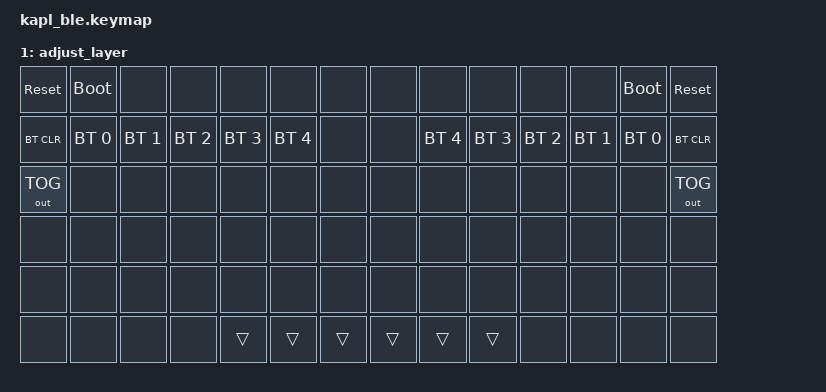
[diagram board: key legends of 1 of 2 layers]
/*
 * Copyright (c) 2021 The ZMK Contributors
 *
 * SPDX-License-Identifier: MIT
 */

#include <behaviors.dtsi>
#include <dt-bindings/zmk/keys.h>
#include <dt-bindings/zmk/bt.h>
#include <dt-bindings/zmk/outputs.h>

#define DEF 0
#define ADJ 1

&lt { quick-tap-ms = <200>; };
&mt { quick-tap-ms = <200>; };

/ {
    keymap {
        compatible =  "zmk,keymap";

				default_layer {
						bindings = <
		&kp ESC   &kp N1   &kp N2   &kp N3   &kp N4   &kp N5   &kp N6             &kp N5    &kp N6    &kp N7   &kp N8    &kp N9    &kp N0     &kp BSPC
		&kp TAB   &kp Q    &kp W    &kp E    &kp R    &kp T    &kp LPAR           &kp RPAR  &kp Y     &kp U    &kp I     &kp O     &kp P      &kp MINUS
		&kp LCTRL &kp A    &kp S    &kp D    &kp F    &kp G    &kp LBKT           &kp RBKT  &kp H     &kp J    &kp K     &kp L     &kp SEMI   &kp SQT
		&kp LSHFT &kp Z    &kp X    &kp C    &kp V    &kp B    &kp PG_UP          &kp PG_DN &kp HOME  &kp END  &kp N     &kp M     &kp COMMA  &kp DOT
		&kp LCTRL &kp LWIN &kp LALT &kp LALT &mo ADJ  &kp BSPC &kp ENTER          &kp DEL   &kp SPACE &mo ADJ  &kp LEFT  &kp DOWN  &kp UP     &kp RIGHT
						>;
				};


				adjust_layer {
						bindings = <
	&sys_reset    &bootloader   &none         &none         &none         &none         &none            &none    &none         &none         &none         &none         &bootloader   &sys_reset
	&bt BT_CLR    &bt BT_SEL 0  &bt BT_SEL 1  &bt BT_SEL 2  &bt BT_SEL 3  &bt BT_SEL 4  &none            &none    &bt BT_SEL 4  &bt BT_SEL 3  &bt BT_SEL 2  &bt BT_SEL 1  &bt BT_SEL 0  &bt BT_CLR
	&out OUT_TOG  &none         &none         &none         &none         &none         &none            &none    &none         &none         &none         &none         &none         &out OUT_TOG
	&none         &none         &none         &none         &none         &none         &none            &none    &none         &none         &none         &none         &none         &none
	&none         &none         &none         &none         &none         &none         &none            &none    &none         &none         &none         &none         &none         &none
	&none         &none         &none         &none         &trans        &trans        &trans           &trans   &trans        &trans        &none         &none         &none         &none
						>;
				};

		};
};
